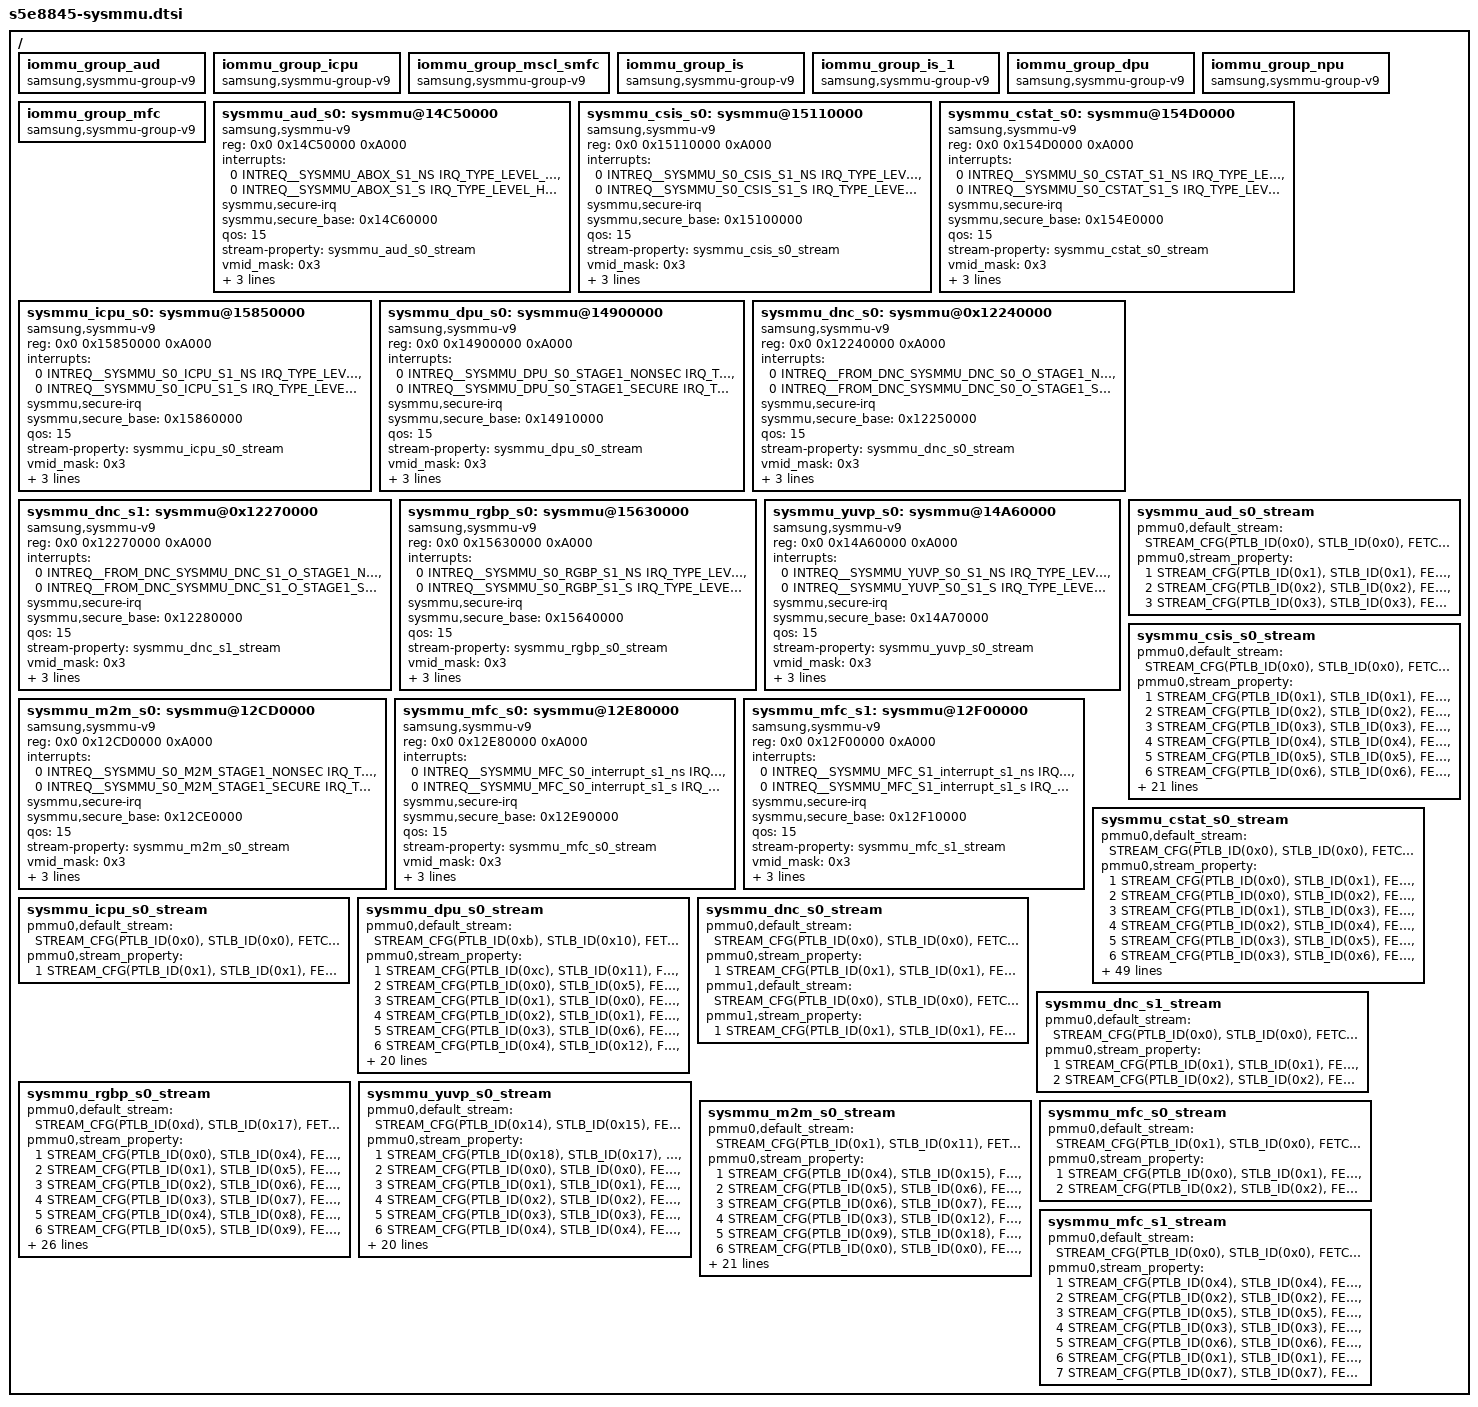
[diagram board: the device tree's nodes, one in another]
// SPDX-License-Identifier: GPL-2.0
/*
 * SAMSUNG S5E8845 SoC device tree source
 *
 * Copyright (c) 2023 Samsung Electronics Co., Ltd.
 *      http://www.samsung.com
 *
 * SAMSUNG S5E8845 SoC device nodes are listed in this file.
 * S5E8845 based board files can include this file and provide
 * values for board specific bindings.
 *
 * This program is free software; you can redistribute it and/or modify
 * it under the terms of the GNU General Public License version 2 as
 * published by the Free Software Foundation.
 */

#include <dt-bindings/interrupt-controller/arm-gic.h>
#include <dt-bindings/soc/samsung,sysmmu-v9.h>

/ {
	iommu_group_aud: iommu_group_aud {
		compatible = "samsung,sysmmu-group-v9";
	};

	iommu_group_icpu: iommu_group_icpu {
		compatible = "samsung,sysmmu-group-v9";
	};

	iommu_group_mscl_smfc: iommu_group_mscl_smfc {
		compatible = "samsung,sysmmu-group-v9";
	};

	iommu_group_is: iommu_group_is {
		compatible = "samsung,sysmmu-group-v9";
	};

	iommu_group_is_1: iommu_group_is_1 {
		compatible = "samsung,sysmmu-group-v9";
	};

	iommu_group_dpu: iommu_group_dpu {
		compatible = "samsung,sysmmu-group-v9";
	};

	iommu_group_npu: iommu_group_npu {
		compatible = "samsung,sysmmu-group-v9";
	};

	iommu_group_mfc: iommu_group_mfc {
		compatible = "samsung,sysmmu-group-v9";
	};

	sysmmu_aud_s0: sysmmu@14C50000 {
		compatible = "samsung,sysmmu-v9";
		reg = <0x0 0x14C50000 0xA000>;
		interrupts = <0 INTREQ__SYSMMU_ABOX_S1_NS IRQ_TYPE_LEVEL_HIGH>,
				<0 INTREQ__SYSMMU_ABOX_S1_S IRQ_TYPE_LEVEL_HIGH>;
		sysmmu,secure-irq;
		sysmmu,secure_base = <0x14C60000>;
		qos = <15>;
		#iommu-cells = <0>;
		stream-property = <&sysmmu_aud_s0_stream>;
		vmid_mask = <0x3>;
		sysmmu,feature-info = <0x1>;
		power-domains = <&pd_aud>;
		port-name = "AUD S0";
	};

	sysmmu_csis_s0: sysmmu@15110000 {
		compatible = "samsung,sysmmu-v9";
		reg = <0x0 0x15110000 0xA000>;
		interrupts = <0 INTREQ__SYSMMU_S0_CSIS_S1_NS IRQ_TYPE_LEVEL_HIGH>,
				<0 INTREQ__SYSMMU_S0_CSIS_S1_S IRQ_TYPE_LEVEL_HIGH>;
		sysmmu,secure-irq;
		sysmmu,secure_base = <0x15100000>;
		qos = <15>;
		#iommu-cells = <0>;
		stream-property = <&sysmmu_csis_s0_stream>;
		vmid_mask = <0x3>;
		sysmmu,feature-info = <0x1>;
		power-domains = <&pd_csis>;
		port-name = "CSIS S0";
	};

	sysmmu_cstat_s0: sysmmu@154D0000 {
		compatible = "samsung,sysmmu-v9";
		reg = <0x0 0x154D0000 0xA000>;
		interrupts = <0 INTREQ__SYSMMU_S0_CSTAT_S1_NS IRQ_TYPE_LEVEL_HIGH>,
				<0 INTREQ__SYSMMU_S0_CSTAT_S1_S IRQ_TYPE_LEVEL_HIGH>;
		sysmmu,secure-irq;
		sysmmu,secure_base = <0x154E0000>;
		qos = <15>;
		#iommu-cells = <0>;
		stream-property = <&sysmmu_cstat_s0_stream>;
		vmid_mask = <0x3>;
		sysmmu,feature-info = <0x1>;
		power-domains = <&pd_cstat>;
		port-name = "CSTAT S0";
	};

	sysmmu_icpu_s0: sysmmu@15850000 {
		compatible = "samsung,sysmmu-v9";
		reg = <0x0 0x15850000 0xA000>;
		interrupts = <0 INTREQ__SYSMMU_S0_ICPU_S1_NS IRQ_TYPE_LEVEL_HIGH>,
				<0 INTREQ__SYSMMU_S0_ICPU_S1_S IRQ_TYPE_LEVEL_HIGH>;
		sysmmu,secure-irq;
		sysmmu,secure_base = <0x15860000>;
		qos = <15>;
		#iommu-cells = <0>;
		stream-property = <&sysmmu_icpu_s0_stream>;
		vmid_mask = <0x3>;
		sysmmu,feature-info = <0x1>;
		power-domains = <&pd_icpu>;
		port-name = "ICPU S0";
	};

	sysmmu_dpu_s0: sysmmu@14900000 {
		compatible = "samsung,sysmmu-v9";
		reg = <0x0 0x14900000 0xA000>;
		interrupts = <0 INTREQ__SYSMMU_DPU_S0_STAGE1_NONSEC IRQ_TYPE_LEVEL_HIGH>,
				<0 INTREQ__SYSMMU_DPU_S0_STAGE1_SECURE IRQ_TYPE_LEVEL_HIGH>;
		sysmmu,secure-irq;
		sysmmu,secure_base = <0x14910000>;
		qos = <15>;
		#iommu-cells = <0>;
		stream-property = <&sysmmu_dpu_s0_stream>;
		vmid_mask = <0x3>;
		sysmmu,feature-info = <0x1>;
		port-name = "DPU_DMA_TOP";
		power-domains = <&pd_dpu>;
	};

	sysmmu_dnc_s0: sysmmu@0x12240000 {
		compatible = "samsung,sysmmu-v9";
		reg = <0x0 0x12240000 0xA000>;
		interrupts = <0 INTREQ__FROM_DNC_SYSMMU_DNC_S0_O_STAGE1_NONSEC IRQ_TYPE_LEVEL_HIGH>,
				<0 INTREQ__FROM_DNC_SYSMMU_DNC_S0_O_STAGE1_SECURE IRQ_TYPE_LEVEL_HIGH>;
		sysmmu,secure-irq;
		sysmmu,secure_base = <0x12250000>;
		qos = <15>;
		#iommu-cells = <0>;
		stream-property = <&sysmmu_dnc_s0_stream>;
		vmid_mask = <0x3>;
		sysmmu,feature-info = <0x1>;
		power-domains = <&pd_dnc>;
		port-name = "DNC S0";
	};

	sysmmu_dnc_s1: sysmmu@0x12270000 {
		compatible = "samsung,sysmmu-v9";
		reg = <0x0 0x12270000 0xA000>;
		interrupts = <0 INTREQ__FROM_DNC_SYSMMU_DNC_S1_O_STAGE1_NONSEC IRQ_TYPE_LEVEL_HIGH>,
				<0 INTREQ__FROM_DNC_SYSMMU_DNC_S1_O_STAGE1_SECURE IRQ_TYPE_LEVEL_HIGH>;
		sysmmu,secure-irq;
		sysmmu,secure_base = <0x12280000>;
		qos = <15>;
		#iommu-cells = <0>;
		stream-property = <&sysmmu_dnc_s1_stream>;
		vmid_mask = <0x3>;
		sysmmu,feature-info = <0x1>;
		power-domains = <&pd_dnc>;
		port-name = "DNC S1";
	};

	sysmmu_rgbp_s0: sysmmu@15630000 {
		compatible = "samsung,sysmmu-v9";
		reg = <0x0 0x15630000 0xA000>;
		interrupts = <0 INTREQ__SYSMMU_S0_RGBP_S1_NS IRQ_TYPE_LEVEL_HIGH>,
				<0 INTREQ__SYSMMU_S0_RGBP_S1_S IRQ_TYPE_LEVEL_HIGH>;
		sysmmu,secure-irq;
		sysmmu,secure_base = <0x15640000>;
		qos = <15>;
		#iommu-cells = <0>;
		stream-property = <&sysmmu_rgbp_s0_stream>;
		vmid_mask = <0x3>;
		sysmmu,feature-info = <0x1>;
		power-domains = <&pd_rgbp>;
		port-name = "RGBP S0";
	};

	sysmmu_yuvp_s0: sysmmu@14A60000 {
		compatible = "samsung,sysmmu-v9";
		reg = <0x0 0x14A60000 0xA000>;
		interrupts = <0 INTREQ__SYSMMU_YUVP_S0_S1_NS IRQ_TYPE_LEVEL_HIGH>,
				<0 INTREQ__SYSMMU_YUVP_S0_S1_S IRQ_TYPE_LEVEL_HIGH>;
		sysmmu,secure-irq;
		sysmmu,secure_base = <0x14A70000>;
		qos = <15>;
		#iommu-cells = <0>;
		stream-property = <&sysmmu_yuvp_s0_stream>;
		vmid_mask = <0x3>;
		sysmmu,feature-info = <0x1>;
		power-domains = <&pd_yuvp>;
		port-name = "YUVP S0";
	};

	sysmmu_m2m_s0: sysmmu@12CD0000 {
		compatible = "samsung,sysmmu-v9";
		reg = <0x0 0x12CD0000 0xA000>;
		interrupts = <0 INTREQ__SYSMMU_S0_M2M_STAGE1_NONSEC IRQ_TYPE_LEVEL_HIGH>,
				<0 INTREQ__SYSMMU_S0_M2M_STAGE1_SECURE IRQ_TYPE_LEVEL_HIGH>;
		sysmmu,secure-irq;
		sysmmu,secure_base = <0x12CE0000>;
		qos = <15>;
		#iommu-cells = <0>;
		stream-property = <&sysmmu_m2m_s0_stream>;
		vmid_mask = <0x3>;
		sysmmu,feature-info = <0x1>;
		power-domains = <&pd_m2m>;
		port-name = "M2M S0";
	};

	sysmmu_mfc_s0: sysmmu@12E80000 {
		compatible = "samsung,sysmmu-v9";
		reg = <0x0 0x12E80000 0xA000>;
		interrupts = <0 INTREQ__SYSMMU_MFC_S0_interrupt_s1_ns IRQ_TYPE_LEVEL_HIGH>,
				<0 INTREQ__SYSMMU_MFC_S0_interrupt_s1_s IRQ_TYPE_LEVEL_HIGH>;
		sysmmu,secure-irq;
		sysmmu,secure_base = <0x12E90000>;
		qos = <15>;
		#iommu-cells = <0>;
		stream-property = <&sysmmu_mfc_s0_stream>;
		vmid_mask = <0x3>;
		sysmmu,feature-info = <0x1>;
		power-domains = <&pd_mfc>;
		port-name = "MFC S0";
	};

	sysmmu_mfc_s1: sysmmu@12F00000 {
		compatible = "samsung,sysmmu-v9";
		reg = <0x0 0x12F00000 0xA000>;
		interrupts = <0 INTREQ__SYSMMU_MFC_S1_interrupt_s1_ns IRQ_TYPE_LEVEL_HIGH>,
				<0 INTREQ__SYSMMU_MFC_S1_interrupt_s1_s IRQ_TYPE_LEVEL_HIGH>;
		sysmmu,secure-irq;
		sysmmu,secure_base = <0x12F10000>;
		qos = <15>;
		#iommu-cells = <0>;
		stream-property = <&sysmmu_mfc_s1_stream>;
		vmid_mask = <0x3>;
		sysmmu,feature-info = <0x1>;
		power-domains = <&pd_mfc>;
		port-name = "MFC S1";
	};

	sysmmu_aud_s0_stream: sysmmu_aud_s0_stream {
		pmmu0,default_stream =
		<STREAM_CFG(PTLB_ID(0x0), STLB_ID(0x0), FETCH_SIZE(SIZE1), PTLB_DIS, STLB_DIS)>;
		pmmu0,stream_property =
		<1 STREAM_CFG(PTLB_ID(0x1), STLB_ID(0x1), FETCH_SIZE(SIZE1), PTLB_DIS, STLB_DIS)
		 STREAM_MATCH_CFG(DIR_RW)
		 STREAM_MATCH_SID_VALUE(0x5)
		 STREAM_MATCH_SID_MASK(0xF)>,
		<2 STREAM_CFG(PTLB_ID(0x2), STLB_ID(0x2), FETCH_SIZE(SIZE1), PTLB_DIS, STLB_DIS)
		 STREAM_MATCH_CFG(DIR_WRITE)
		 STREAM_MATCH_SID_VALUE(0x6)
		 STREAM_MATCH_SID_MASK(0xF)>,
		<3 STREAM_CFG(PTLB_ID(0x3), STLB_ID(0x3), FETCH_SIZE(SIZE1), PTLB_DIS, STLB_DIS)
		 STREAM_MATCH_CFG(DIR_WRITE)
		 STREAM_MATCH_SID_VALUE(0x7)
		 STREAM_MATCH_SID_MASK(0xF)>;
	};

	sysmmu_csis_s0_stream: sysmmu_csis_s0_stream {
		pmmu0,default_stream =
		<STREAM_CFG(PTLB_ID(0x0), STLB_ID(0x0), FETCH_SIZE(SIZE1), PTLB_EN, STLB_EN)>;
		pmmu0,stream_property =
		<1 STREAM_CFG(PTLB_ID(0x1), STLB_ID(0x1), FETCH_SIZE(SIZE1), PTLB_EN, STLB_EN)
		 STREAM_MATCH_CFG(DIR_WRITE)
		 STREAM_MATCH_SID_VALUE(0x2)
		 STREAM_MATCH_SID_MASK(0xF)>,
		<2 STREAM_CFG(PTLB_ID(0x2), STLB_ID(0x2), FETCH_SIZE(SIZE1), PTLB_EN, STLB_EN)
		 STREAM_MATCH_CFG(DIR_WRITE)
		 STREAM_MATCH_SID_VALUE(0x4)
		 STREAM_MATCH_SID_MASK(0xF)>,
		<3 STREAM_CFG(PTLB_ID(0x3), STLB_ID(0x3), FETCH_SIZE(SIZE1), PTLB_EN, STLB_EN)
		 STREAM_MATCH_CFG(DIR_WRITE)
		 STREAM_MATCH_SID_VALUE(0x8)
		 STREAM_MATCH_SID_MASK(0xF)>,
		<4 STREAM_CFG(PTLB_ID(0x4), STLB_ID(0x4), FETCH_SIZE(SIZE1), PTLB_EN, STLB_EN)
		 STREAM_MATCH_CFG(DIR_WRITE)
		 STREAM_MATCH_SID_VALUE(0xC)
		 STREAM_MATCH_SID_MASK(0xF)>,
		<5 STREAM_CFG(PTLB_ID(0x5), STLB_ID(0x5), FETCH_SIZE(SIZE1), PTLB_EN, STLB_EN)
		 STREAM_MATCH_CFG(DIR_WRITE)
		 STREAM_MATCH_SID_VALUE(0x1)
		 STREAM_MATCH_SID_MASK(0xF)>,
		<6 STREAM_CFG(PTLB_ID(0x6), STLB_ID(0x6), FETCH_SIZE(SIZE1), PTLB_EN, STLB_EN)
		 STREAM_MATCH_CFG(DIR_WRITE)
		 STREAM_MATCH_SID_VALUE(0x3)
		 STREAM_MATCH_SID_MASK(0xF)>,
		<7 STREAM_CFG(PTLB_ID(0x7), STLB_ID(0x7), FETCH_SIZE(SIZE1), PTLB_EN, STLB_EN)
		 STREAM_MATCH_CFG(DIR_WRITE)
		 STREAM_MATCH_SID_VALUE(0x5)
		 STREAM_MATCH_SID_MASK(0xF)>,
		<8 STREAM_CFG(PTLB_ID(0x8), STLB_ID(0x8), FETCH_SIZE(SIZE1), PTLB_EN, STLB_EN)
		 STREAM_MATCH_CFG(DIR_WRITE)
		 STREAM_MATCH_SID_VALUE(0x9)
		 STREAM_MATCH_SID_MASK(0xF)>,
		<9 STREAM_CFG(PTLB_ID(0x9), STLB_ID(0x9), FETCH_SIZE(SIZE1), PTLB_EN, STLB_EN)
		 STREAM_MATCH_CFG(DIR_WRITE)
		 STREAM_MATCH_SID_VALUE(0xD)
		 STREAM_MATCH_SID_MASK(0xF)>;
		pmmu1,default_stream =
		<STREAM_CFG(PTLB_ID(0x0), STLB_ID(0xA), FETCH_SIZE(SIZE1), PTLB_EN, STLB_EN)>;
		pmmu1,stream_property =
		<1 STREAM_CFG(PTLB_ID(0x1), STLB_ID(0xB), FETCH_SIZE(SIZE1), PTLB_EN, STLB_EN)
		 STREAM_MATCH_CFG(DIR_WRITE)
		 STREAM_MATCH_SID_VALUE(0x8)
		 STREAM_MATCH_SID_MASK(0xFF)>,
		<2 STREAM_CFG(PTLB_ID(0x2), STLB_ID(0xC), FETCH_SIZE(SIZE1), PTLB_EN, STLB_EN)
		 STREAM_MATCH_CFG(DIR_WRITE)
		 STREAM_MATCH_SID_VALUE(0x10)
		 STREAM_MATCH_SID_MASK(0xFF)>,
		<3 STREAM_CFG(PTLB_ID(0x3), STLB_ID(0xD), FETCH_SIZE(SIZE1), PTLB_EN, STLB_EN)
		 STREAM_MATCH_CFG(DIR_WRITE)
		 STREAM_MATCH_SID_VALUE(0x20)
		 STREAM_MATCH_SID_MASK(0xFF)>,
		<4 STREAM_CFG(PTLB_ID(0x4), STLB_ID(0xE), FETCH_SIZE(SIZE1), PTLB_EN, STLB_EN)
		 STREAM_MATCH_CFG(DIR_WRITE)
		 STREAM_MATCH_SID_VALUE(0x30)
		 STREAM_MATCH_SID_MASK(0xFF)>,
		<5 STREAM_CFG(PTLB_ID(0x5), STLB_ID(0xF), FETCH_SIZE(SIZE1), PTLB_EN, STLB_EN)
		 STREAM_MATCH_CFG(DIR_WRITE)
		 STREAM_MATCH_SID_VALUE(0x1)
		 STREAM_MATCH_SID_MASK(0xFF)>,
		<6 STREAM_CFG(PTLB_ID(0x6), STLB_ID(0x10), FETCH_SIZE(SIZE1), PTLB_EN, STLB_EN)
		 STREAM_MATCH_CFG(DIR_WRITE)
		 STREAM_MATCH_SID_VALUE(0x9)
		 STREAM_MATCH_SID_MASK(0xFF)>,
		<7 STREAM_CFG(PTLB_ID(0x7), STLB_ID(0x11), FETCH_SIZE(SIZE1), PTLB_EN, STLB_EN)
		 STREAM_MATCH_CFG(DIR_WRITE)
		 STREAM_MATCH_SID_VALUE(0x11)
		 STREAM_MATCH_SID_MASK(0xFF)>,
		<8 STREAM_CFG(PTLB_ID(0x8), STLB_ID(0x12), FETCH_SIZE(SIZE1), PTLB_EN, STLB_EN)
		 STREAM_MATCH_CFG(DIR_WRITE)
		 STREAM_MATCH_SID_VALUE(0x21)
		 STREAM_MATCH_SID_MASK(0xFF)>,
		<9 STREAM_CFG(PTLB_ID(0x9), STLB_ID(0x13), FETCH_SIZE(SIZE1), PTLB_EN, STLB_EN)
		 STREAM_MATCH_CFG(DIR_WRITE)
		 STREAM_MATCH_SID_VALUE(0x31)
		 STREAM_MATCH_SID_MASK(0xFF)>,
		<10 STREAM_CFG(PTLB_ID(0xA), STLB_ID(0x14), FETCH_SIZE(SIZE1), PTLB_EN, STLB_EN)
		 STREAM_MATCH_CFG(DIR_READ)
		 STREAM_MATCH_SID_VALUE(0x2)
		 STREAM_MATCH_SID_MASK(0xFF)>,
		<11 STREAM_CFG(PTLB_ID(0xB), STLB_ID(0x15), FETCH_SIZE(SIZE1), PTLB_EN, STLB_EN)
		 STREAM_MATCH_CFG(DIR_WRITE)
		 STREAM_MATCH_SID_VALUE(0x2)
		 STREAM_MATCH_SID_MASK(0xFF)>,
		<12 STREAM_CFG(PTLB_ID(0xC), STLB_ID(0x16), FETCH_SIZE(SIZE1), PTLB_EN, STLB_EN)
		 STREAM_MATCH_CFG(DIR_WRITE)
		 STREAM_MATCH_SID_VALUE(0x42)
		 STREAM_MATCH_SID_MASK(0xFF)>,
		<13 STREAM_CFG(PTLB_ID(0xD), STLB_ID(0x17), FETCH_SIZE(SIZE1), PTLB_EN, STLB_EN)
		 STREAM_MATCH_CFG(DIR_WRITE)
		 STREAM_MATCH_SID_VALUE(0x82)
		 STREAM_MATCH_SID_MASK(0xFF)>,
		<14 STREAM_CFG(PTLB_ID(0xF), STLB_ID(0x19), FETCH_SIZE(SIZE1), PTLB_EN, STLB_DIS)
		 STREAM_MATCH_CFG(DIR_WRITE)
		 STREAM_MATCH_SID_VALUE(0x3)
		 STREAM_MATCH_SID_MASK(0x1)>,
		<15 STREAM_CFG(PTLB_ID(0xE), STLB_ID(0x18), FETCH_SIZE(SIZE1), PTLB_EN, STLB_DIS)
		 STREAM_MATCH_CFG(DIR_WRITE)
		 STREAM_MATCH_SID_VALUE(0x4)
		 STREAM_MATCH_SID_MASK(0x1)>;
	};

	sysmmu_cstat_s0_stream: sysmmu_cstat_s0_stream {
		pmmu0,default_stream =
		<STREAM_CFG(PTLB_ID(0x0), STLB_ID(0x0), FETCH_SIZE(SIZE1), PTLB_DIS, STLB_EN)>;
		pmmu0,stream_property =
		<1 STREAM_CFG(PTLB_ID(0x0), STLB_ID(0x1), FETCH_SIZE(SIZE1), PTLB_DIS, STLB_EN)
		 STREAM_MATCH_CFG(DIR_WRITE)
		 STREAM_MATCH_SID_VALUE(0x80)
		 STREAM_MATCH_SID_MASK(0x1FF)>,
		<2 STREAM_CFG(PTLB_ID(0x0), STLB_ID(0x2), FETCH_SIZE(SIZE1), PTLB_DIS, STLB_EN)
		 STREAM_MATCH_CFG(DIR_WRITE)
		 STREAM_MATCH_SID_VALUE(0x100)
		 STREAM_MATCH_SID_MASK(0x1FF)>,
		<3 STREAM_CFG(PTLB_ID(0x1), STLB_ID(0x3), FETCH_SIZE(SIZE1), PTLB_EN, STLB_EN)
		 STREAM_MATCH_CFG(DIR_READ)
		 STREAM_MATCH_SID_VALUE(0x0)
		 STREAM_MATCH_SID_MASK(0x1)>,
		<4 STREAM_CFG(PTLB_ID(0x2), STLB_ID(0x4), FETCH_SIZE(SIZE1), PTLB_EN, STLB_EN)
		 STREAM_MATCH_CFG(DIR_READ)
		 STREAM_MATCH_SID_VALUE(0x10)
		 STREAM_MATCH_SID_MASK(0x1)>,
		<5 STREAM_CFG(PTLB_ID(0x3), STLB_ID(0x5), FETCH_SIZE(SIZE1), PTLB_DIS, STLB_EN)
		 STREAM_MATCH_CFG(DIR_WRITE)
		 STREAM_MATCH_SID_VALUE(0x1)
		 STREAM_MATCH_SID_MASK(0x1F)>,
		<6 STREAM_CFG(PTLB_ID(0x3), STLB_ID(0x6), FETCH_SIZE(SIZE1), PTLB_DIS, STLB_EN)
		 STREAM_MATCH_CFG(DIR_WRITE)
		 STREAM_MATCH_SID_VALUE(0x21)
		 STREAM_MATCH_SID_MASK(0x1F)>,
		<7 STREAM_CFG(PTLB_ID(0x3), STLB_ID(0x7), FETCH_SIZE(SIZE1), PTLB_DIS, STLB_EN)
		 STREAM_MATCH_CFG(DIR_WRITE)
		 STREAM_MATCH_SID_VALUE(0x41)
		 STREAM_MATCH_SID_MASK(0x1F)>,
		<8 STREAM_CFG(PTLB_ID(0x4), STLB_ID(0x8), FETCH_SIZE(SIZE1), PTLB_EN, STLB_EN)
		 STREAM_MATCH_CFG(DIR_READ)
		 STREAM_MATCH_SID_VALUE(0x1)
		 STREAM_MATCH_SID_MASK(0x1)>,
		<9 STREAM_CFG(PTLB_ID(0x5), STLB_ID(0x9), FETCH_SIZE(SIZE1), PTLB_DIS, STLB_EN)
		 STREAM_MATCH_CFG(DIR_WRITE)
		 STREAM_MATCH_SID_VALUE(0x2)
		 STREAM_MATCH_SID_MASK(0x1F)>,
		<10 STREAM_CFG(PTLB_ID(0x5), STLB_ID(0xA), FETCH_SIZE(SIZE1), PTLB_DIS, STLB_EN)
		 STREAM_MATCH_CFG(DIR_WRITE)
		 STREAM_MATCH_SID_VALUE(0x82)
		 STREAM_MATCH_SID_MASK(0x1F)>,
		<11 STREAM_CFG(PTLB_ID(0x5), STLB_ID(0xB), FETCH_SIZE(SIZE1), PTLB_DIS, STLB_EN)
		 STREAM_MATCH_CFG(DIR_WRITE)
		 STREAM_MATCH_SID_VALUE(0x102)
		 STREAM_MATCH_SID_MASK(0x1F)>,
		<12 STREAM_CFG(PTLB_ID(0x6), STLB_ID(0xC), FETCH_SIZE(SIZE1), PTLB_EN, STLB_EN)
		 STREAM_MATCH_CFG(DIR_READ)
		 STREAM_MATCH_SID_VALUE(0x2)
		 STREAM_MATCH_SID_MASK(0x1)>,
		<13 STREAM_CFG(PTLB_ID(0x7), STLB_ID(0xD), FETCH_SIZE(SIZE1), PTLB_DIS, STLB_EN)
		 STREAM_MATCH_CFG(DIR_WRITE)
		 STREAM_MATCH_SID_VALUE(0x3)
		 STREAM_MATCH_SID_MASK(0x1F)>,
		<14 STREAM_CFG(PTLB_ID(0x7), STLB_ID(0xE), FETCH_SIZE(SIZE1), PTLB_DIS, STLB_EN)
		 STREAM_MATCH_CFG(DIR_WRITE)
		 STREAM_MATCH_SID_VALUE(0x83)
		 STREAM_MATCH_SID_MASK(0x1F)>,
		<15 STREAM_CFG(PTLB_ID(0x7), STLB_ID(0xF), FETCH_SIZE(SIZE1), PTLB_DIS, STLB_EN)
		 STREAM_MATCH_CFG(DIR_WRITE)
		 STREAM_MATCH_SID_VALUE(0x103)
		 STREAM_MATCH_SID_MASK(0x1F)>,
		<16 STREAM_CFG(PTLB_ID(0x8), STLB_ID(0x10), FETCH_SIZE(SIZE1), PTLB_DIS, STLB_EN)
		 STREAM_MATCH_CFG(DIR_WRITE)
		 STREAM_MATCH_SID_VALUE(0x4)
		 STREAM_MATCH_SID_MASK(0x1F)>,
		<17 STREAM_CFG(PTLB_ID(0x8), STLB_ID(0x11), FETCH_SIZE(SIZE1), PTLB_DIS, STLB_EN)
		 STREAM_MATCH_CFG(DIR_WRITE)
		 STREAM_MATCH_SID_VALUE(0x84)
		 STREAM_MATCH_SID_MASK(0x1F)>,
		<18 STREAM_CFG(PTLB_ID(0x8), STLB_ID(0x12), FETCH_SIZE(SIZE1), PTLB_DIS, STLB_EN)
		 STREAM_MATCH_CFG(DIR_WRITE)
		 STREAM_MATCH_SID_VALUE(0x104)
		 STREAM_MATCH_SID_MASK(0x1F)>,
		<19 STREAM_CFG(PTLB_ID(0x10), STLB_ID(0x2F), FETCH_SIZE(SIZE1), PTLB_DIS, STLB_DIS)
		 STREAM_MATCH_CFG(DIR_READ)
		 STREAM_MATCH_SID_VALUE(0x4)
		 STREAM_MATCH_SID_MASK(0x1)>,
		<20 STREAM_CFG(PTLB_ID(0x9), STLB_ID(0x13), FETCH_SIZE(SIZE1), PTLB_DIS, STLB_EN)
		 STREAM_MATCH_CFG(DIR_WRITE)
		 STREAM_MATCH_SID_VALUE(0x5)
		 STREAM_MATCH_SID_MASK(0x1F)>,
		<21 STREAM_CFG(PTLB_ID(0x9), STLB_ID(0x14), FETCH_SIZE(SIZE1), PTLB_DIS, STLB_EN)
		 STREAM_MATCH_CFG(DIR_WRITE)
		 STREAM_MATCH_SID_VALUE(0x85)
		 STREAM_MATCH_SID_MASK(0x1F)>,
		<22 STREAM_CFG(PTLB_ID(0x9), STLB_ID(0x15), FETCH_SIZE(SIZE1), PTLB_DIS, STLB_EN)
		 STREAM_MATCH_CFG(DIR_WRITE)
		 STREAM_MATCH_SID_VALUE(0x105)
		 STREAM_MATCH_SID_MASK(0x1F)>,
		<23 STREAM_CFG(PTLB_ID(0x11), STLB_ID(0x30), FETCH_SIZE(SIZE1), PTLB_DIS, STLB_DIS)
		 STREAM_MATCH_CFG(DIR_READ)
		 STREAM_MATCH_SID_VALUE(0x5)
		 STREAM_MATCH_SID_MASK(0x1)>,
		<24 STREAM_CFG(PTLB_ID(0xA), STLB_ID(0x16), FETCH_SIZE(SIZE1), PTLB_DIS, STLB_EN)
		 STREAM_MATCH_CFG(DIR_WRITE)
		 STREAM_MATCH_SID_VALUE(0x6)
		 STREAM_MATCH_SID_MASK(0x1F)>,
		<25 STREAM_CFG(PTLB_ID(0xA), STLB_ID(0x17), FETCH_SIZE(SIZE1), PTLB_DIS, STLB_EN)
		 STREAM_MATCH_CFG(DIR_WRITE)
		 STREAM_MATCH_SID_VALUE(0x86)
		 STREAM_MATCH_SID_MASK(0x1F)>,
		<26 STREAM_CFG(PTLB_ID(0xA), STLB_ID(0x18), FETCH_SIZE(SIZE1), PTLB_DIS, STLB_EN)
		 STREAM_MATCH_CFG(DIR_WRITE)
		 STREAM_MATCH_SID_VALUE(0x106)
		 STREAM_MATCH_SID_MASK(0x1F)>,
		<27 STREAM_CFG(PTLB_ID(0x12), STLB_ID(0x31), FETCH_SIZE(SIZE1), PTLB_DIS, STLB_DIS)
		 STREAM_MATCH_CFG(DIR_READ)
		 STREAM_MATCH_SID_VALUE(0x6)
		 STREAM_MATCH_SID_MASK(0x1)>,
		<28 STREAM_CFG(PTLB_ID(0xB), STLB_ID(0x19), FETCH_SIZE(SIZE1), PTLB_DIS, STLB_EN)
		 STREAM_MATCH_CFG(DIR_WRITE)
		 STREAM_MATCH_SID_VALUE(0x7)
		 STREAM_MATCH_SID_MASK(0x1F)>,
		<29 STREAM_CFG(PTLB_ID(0xB), STLB_ID(0x1A), FETCH_SIZE(SIZE1), PTLB_DIS, STLB_EN)
		 STREAM_MATCH_CFG(DIR_WRITE)
		 STREAM_MATCH_SID_VALUE(0x87)
		 STREAM_MATCH_SID_MASK(0x1F)>,
		<30 STREAM_CFG(PTLB_ID(0xB), STLB_ID(0x1B), FETCH_SIZE(SIZE1), PTLB_DIS, STLB_EN)
		 STREAM_MATCH_CFG(DIR_WRITE)
		 STREAM_MATCH_SID_VALUE(0x107)
		 STREAM_MATCH_SID_MASK(0x1F)>,
		<31 STREAM_CFG(PTLB_ID(0xC), STLB_ID(0x1C), FETCH_SIZE(SIZE1), PTLB_DIS, STLB_EN)
		 STREAM_MATCH_CFG(DIR_WRITE)
		 STREAM_MATCH_SID_VALUE(0x9)
		 STREAM_MATCH_SID_MASK(0x1F)>,
		<32 STREAM_CFG(PTLB_ID(0xC), STLB_ID(0x1D), FETCH_SIZE(SIZE1), PTLB_DIS, STLB_EN)
		 STREAM_MATCH_CFG(DIR_WRITE)
		 STREAM_MATCH_SID_VALUE(0x89)
		 STREAM_MATCH_SID_MASK(0x1F)>,
		<33 STREAM_CFG(PTLB_ID(0xC), STLB_ID(0x1E), FETCH_SIZE(SIZE1), PTLB_DIS, STLB_EN)
		 STREAM_MATCH_CFG(DIR_WRITE)
		 STREAM_MATCH_SID_VALUE(0x109)
		 STREAM_MATCH_SID_MASK(0x1F)>,
		<34 STREAM_CFG(PTLB_ID(0xD), STLB_ID(0x1F), FETCH_SIZE(SIZE1), PTLB_DIS, STLB_EN)
		 STREAM_MATCH_CFG(DIR_WRITE)
		 STREAM_MATCH_SID_VALUE(0x9)
		 STREAM_MATCH_SID_MASK(0x1F)>,
		<35 STREAM_CFG(PTLB_ID(0xD), STLB_ID(0x20), FETCH_SIZE(SIZE1), PTLB_DIS, STLB_EN)
		 STREAM_MATCH_CFG(DIR_WRITE)
		 STREAM_MATCH_SID_VALUE(0x89)
		 STREAM_MATCH_SID_MASK(0x1F)>,
		<36 STREAM_CFG(PTLB_ID(0xD), STLB_ID(0x21), FETCH_SIZE(SIZE1), PTLB_DIS, STLB_EN)
		 STREAM_MATCH_CFG(DIR_WRITE)
		 STREAM_MATCH_SID_VALUE(0x109)
		 STREAM_MATCH_SID_MASK(0x1F)>,
		<37 STREAM_CFG(PTLB_ID(0xE), STLB_ID(0x22), FETCH_SIZE(SIZE1), PTLB_DIS, STLB_EN)
		 STREAM_MATCH_CFG(DIR_WRITE)
		 STREAM_MATCH_SID_VALUE(0x189)
		 STREAM_MATCH_SID_MASK(0x1F)>,
		<38 STREAM_CFG(PTLB_ID(0xE), STLB_ID(0x23), FETCH_SIZE(SIZE1), PTLB_DIS, STLB_EN)
		 STREAM_MATCH_CFG(DIR_WRITE)
		 STREAM_MATCH_SID_VALUE(0x29)
		 STREAM_MATCH_SID_MASK(0x1F)>,
		<39 STREAM_CFG(PTLB_ID(0xE), STLB_ID(0x24), FETCH_SIZE(SIZE1), PTLB_DIS, STLB_EN)
		 STREAM_MATCH_CFG(DIR_WRITE)
		 STREAM_MATCH_SID_VALUE(0xA9)
		 STREAM_MATCH_SID_MASK(0x1F)>,
		<40 STREAM_CFG(PTLB_ID(0xF), STLB_ID(0x25), FETCH_SIZE(SIZE1), PTLB_DIS, STLB_EN)
		 STREAM_MATCH_CFG(DIR_WRITE)
		 STREAM_MATCH_SID_VALUE(0x129)
		 STREAM_MATCH_SID_MASK(0x1F)>,
		<41 STREAM_CFG(PTLB_ID(0xF), STLB_ID(0x26), FETCH_SIZE(SIZE1), PTLB_DIS, STLB_EN)
		 STREAM_MATCH_CFG(DIR_WRITE)
		 STREAM_MATCH_SID_VALUE(0x1A9)
		 STREAM_MATCH_SID_MASK(0x1F)>,
		<42 STREAM_CFG(PTLB_ID(0xF), STLB_ID(0x27), FETCH_SIZE(SIZE1), PTLB_DIS, STLB_EN)
		 STREAM_MATCH_CFG(DIR_WRITE)
		 STREAM_MATCH_SID_VALUE(0x9)
		 STREAM_MATCH_SID_MASK(0x1F)>,
		<43 STREAM_CFG(PTLB_ID(0x13), STLB_ID(0x33), FETCH_SIZE(SIZE1), PTLB_DIS, STLB_DIS)
		 STREAM_MATCH_CFG(DIR_WRITE)
		 STREAM_MATCH_SID_VALUE(0xA)
		 STREAM_MATCH_SID_MASK(0x1)>,
		<44 STREAM_CFG(PTLB_ID(0x14), STLB_ID(0x34), FETCH_SIZE(SIZE1), PTLB_DIS, STLB_DIS)
		 STREAM_MATCH_CFG(DIR_WRITE)
		 STREAM_MATCH_SID_VALUE(0xB)
		 STREAM_MATCH_SID_MASK(0x1)>;
		pmmu1,default_stream =
		<STREAM_CFG(PTLB_ID(0x0), STLB_ID(0x28), FETCH_SIZE(SIZE1), PTLB_EN, STLB_EN)>;
		pmmu1,stream_property =
		<1 STREAM_CFG(PTLB_ID(0x7), STLB_ID(0x32), FETCH_SIZE(SIZE1), PTLB_DIS, STLB_DIS)
		 STREAM_MATCH_CFG(DIR_READ)
		 STREAM_MATCH_SID_VALUE(0x0)
		 STREAM_MATCH_SID_MASK(0xF)>,
		<2 STREAM_CFG(PTLB_ID(0x1), STLB_ID(0x29), FETCH_SIZE(SIZE1), PTLB_EN, STLB_EN)
		 STREAM_MATCH_CFG(DIR_READ)
		 STREAM_MATCH_SID_VALUE(0x1)
		 STREAM_MATCH_SID_MASK(0xF)>,
		<3 STREAM_CFG(PTLB_ID(0x2), STLB_ID(0x2A), FETCH_SIZE(SIZE1), PTLB_EN, STLB_EN)
		 STREAM_MATCH_CFG(DIR_READ)
		 STREAM_MATCH_SID_VALUE(0x9)
		 STREAM_MATCH_SID_MASK(0xF)>,
		<4 STREAM_CFG(PTLB_ID(0x3), STLB_ID(0x2B), FETCH_SIZE(SIZE1), PTLB_EN, STLB_EN)
		 STREAM_MATCH_CFG(DIR_WRITE)
		 STREAM_MATCH_SID_VALUE(0x1)
		 STREAM_MATCH_SID_MASK(0xF)>,
		<5 STREAM_CFG(PTLB_ID(0x4), STLB_ID(0x2C), FETCH_SIZE(SIZE1), PTLB_EN, STLB_EN)
		 STREAM_MATCH_CFG(DIR_WRITE)
		 STREAM_MATCH_SID_VALUE(0x2)
		 STREAM_MATCH_SID_MASK(0xF)>,
		<6 STREAM_CFG(PTLB_ID(0x5), STLB_ID(0x2D), FETCH_SIZE(SIZE1), PTLB_EN, STLB_EN)
		 STREAM_MATCH_CFG(DIR_READ)
		 STREAM_MATCH_SID_VALUE(0x3)
		 STREAM_MATCH_SID_MASK(0xF)>,
		<7 STREAM_CFG(PTLB_ID(0x6), STLB_ID(0x2E), FETCH_SIZE(SIZE1), PTLB_EN, STLB_EN)
		 STREAM_MATCH_CFG(DIR_READ)
		 STREAM_MATCH_SID_VALUE(0xB)
		 STREAM_MATCH_SID_MASK(0xF)>,
		<8 STREAM_CFG(PTLB_ID(0x8), STLB_ID(0x35), FETCH_SIZE(SIZE1), PTLB_DIS, STLB_DIS)
		 STREAM_MATCH_CFG(DIR_WRITE)
		 STREAM_MATCH_SID_VALUE(0x4)
		 STREAM_MATCH_SID_MASK(0xF)>;
	};

	sysmmu_icpu_s0_stream: sysmmu_icpu_s0_stream {
		pmmu0,default_stream =
		<STREAM_CFG(PTLB_ID(0x0), STLB_ID(0x0), FETCH_SIZE(SIZE1), PTLB_DIS, STLB_DIS)>;
		pmmu0,stream_property =
		<1 STREAM_CFG(PTLB_ID(0x1), STLB_ID(0x1), FETCH_SIZE(SIZE1), PTLB_DIS, STLB_DIS)
		 STREAM_MATCH_CFG(DIR_RW)
		 STREAM_MATCH_SID_VALUE(0x1)
		 STREAM_MATCH_SID_MASK(0x1)>;
	};

	sysmmu_dpu_s0_stream: sysmmu_dpu_s0_stream {
		pmmu0,default_stream =
		<STREAM_CFG(PTLB_ID(0xb), STLB_ID(0x10), FETCH_SIZE(SIZE1), PTLB_EN, STLB_EN)>;
		pmmu0,stream_property =
		<1 STREAM_CFG(PTLB_ID(0xc), STLB_ID(0x11), FETCH_SIZE(SIZE1), PTLB_EN, STLB_EN)
		 STREAM_MATCH_CFG(DIR_READ)
		 STREAM_MATCH_SID_VALUE(0x1A)
		 STREAM_MATCH_SID_MASK(0x1F)>,
		<2 STREAM_CFG(PTLB_ID(0x0), STLB_ID(0x5), FETCH_SIZE(SIZE2), PTLB_EN, STLB_EN)
		 STREAM_MATCH_CFG(DIR_READ)
		 STREAM_MATCH_SID_VALUE(0x0)
		 STREAM_MATCH_SID_MASK(0x1F)>,
		<3 STREAM_CFG(PTLB_ID(0x1), STLB_ID(0x0), FETCH_SIZE(SIZE32), PTLB_DIS, STLB_EN)
		 STREAM_MATCH_CFG(DIR_READ)
		 STREAM_MATCH_SID_VALUE(0x4)
		 STREAM_MATCH_SID_MASK(0x1F)>,
		<4 STREAM_CFG(PTLB_ID(0x2), STLB_ID(0x1), FETCH_SIZE(SIZE32), PTLB_DIS, STLB_EN)
		 STREAM_MATCH_CFG(DIR_READ)
		 STREAM_MATCH_SID_VALUE(0x5)
		 STREAM_MATCH_SID_MASK(0x1F)>,
		<5 STREAM_CFG(PTLB_ID(0x3), STLB_ID(0x6), FETCH_SIZE(SIZE2), PTLB_EN, STLB_EN)
		 STREAM_MATCH_CFG(DIR_READ)
		 STREAM_MATCH_SID_VALUE(0x6)
		 STREAM_MATCH_SID_MASK(0x1F)>,
		<6 STREAM_CFG(PTLB_ID(0x4), STLB_ID(0x12), FETCH_SIZE(SIZE1), PTLB_EN, STLB_EN)
		 STREAM_MATCH_CFG(DIR_READ)
		 STREAM_MATCH_SID_VALUE(0x7)
		 STREAM_MATCH_SID_MASK(0x1F)>,
		<7 STREAM_CFG(PTLB_ID(0x5), STLB_ID(0x2), FETCH_SIZE(SIZE16), PTLB_EN, STLB_EN)
		 STREAM_MATCH_CFG(DIR_READ)
		 STREAM_MATCH_SID_VALUE(0x8)
		 STREAM_MATCH_SID_MASK(0x1F)>,
		<8 STREAM_CFG(PTLB_ID(0x6), STLB_ID(0x7), FETCH_SIZE(SIZE2), PTLB_EN, STLB_EN)
		 STREAM_MATCH_CFG(DIR_READ)
		 STREAM_MATCH_SID_VALUE(0xA)
		 STREAM_MATCH_SID_MASK(0x1F)>,
		<9 STREAM_CFG(PTLB_ID(0x7), STLB_ID(0x8), FETCH_SIZE(SIZE2), PTLB_EN, STLB_EN)
		 STREAM_MATCH_CFG(DIR_READ)
		 STREAM_MATCH_SID_VALUE(0xC)
		 STREAM_MATCH_SID_MASK(0x1F)>,
		<10 STREAM_CFG(PTLB_ID(0x8), STLB_ID(0x9), FETCH_SIZE(SIZE2), PTLB_EN, STLB_EN)
		 STREAM_MATCH_CFG(DIR_READ)
		 STREAM_MATCH_SID_VALUE(0xD)
		 STREAM_MATCH_SID_MASK(0x1F)>,
		<11 STREAM_CFG(PTLB_ID(0x9), STLB_ID(0x13), FETCH_SIZE(SIZE1), PTLB_EN, STLB_EN)
		 STREAM_MATCH_CFG(DIR_READ)
		 STREAM_MATCH_SID_VALUE(0xE)
		 STREAM_MATCH_SID_MASK(0x1F)>,
		<12 STREAM_CFG(PTLB_ID(0xa), STLB_ID(0x14), FETCH_SIZE(SIZE1), PTLB_EN, STLB_EN)
		 STREAM_MATCH_CFG(DIR_READ)
		 STREAM_MATCH_SID_VALUE(0xF)
		 STREAM_MATCH_SID_MASK(0x1F)>;
		pmmu1,default_stream =
		<STREAM_CFG(PTLB_ID(0xB), STLB_ID(0x18), FETCH_SIZE(SIZE1), PTLB_EN, STLB_DIS)>;
		pmmu1,stream_property =
		<1 STREAM_CFG(PTLB_ID(0x0), STLB_ID(0x3), FETCH_SIZE(SIZE16), PTLB_EN, STLB_EN)
		 STREAM_MATCH_CFG(DIR_READ)
		 STREAM_MATCH_SID_VALUE(0x0)
		 STREAM_MATCH_SID_MASK(0x1F)>,
		<2 STREAM_CFG(PTLB_ID(0x1), STLB_ID(0xA), FETCH_SIZE(SIZE2), PTLB_EN, STLB_EN)
		 STREAM_MATCH_CFG(DIR_READ)
		 STREAM_MATCH_SID_VALUE(0x2)
		 STREAM_MATCH_SID_MASK(0x1F)>,
		<3 STREAM_CFG(PTLB_ID(0x2), STLB_ID(0xb), FETCH_SIZE(SIZE1), PTLB_EN, STLB_EN)
		 STREAM_MATCH_CFG(DIR_READ)
		 STREAM_MATCH_SID_VALUE(0x4)
		 STREAM_MATCH_SID_MASK(0x1F)>,
		<4 STREAM_CFG(PTLB_ID(0x3), STLB_ID(0xc), FETCH_SIZE(SIZE1), PTLB_EN, STLB_EN)
		 STREAM_MATCH_CFG(DIR_READ)
		 STREAM_MATCH_SID_VALUE(0x5)
		 STREAM_MATCH_SID_MASK(0x1F)>,
		<5 STREAM_CFG(PTLB_ID(0x4), STLB_ID(0xd), FETCH_SIZE(SIZE1), PTLB_EN, STLB_EN)
		 STREAM_MATCH_CFG(DIR_READ)
		 STREAM_MATCH_SID_VALUE(0x8)
		 STREAM_MATCH_SID_MASK(0x1F)>,
		<6 STREAM_CFG(PTLB_ID(0x5), STLB_ID(0x4), FETCH_SIZE(SIZE16), PTLB_EN, STLB_EN)
		 STREAM_MATCH_CFG(DIR_READ)
		 STREAM_MATCH_SID_VALUE(0xC)
		 STREAM_MATCH_SID_MASK(0x1F)>,
		<7 STREAM_CFG(PTLB_ID(0x6), STLB_ID(0xe), FETCH_SIZE(SIZE2), PTLB_EN, STLB_EN)
		 STREAM_MATCH_CFG(DIR_READ)
		 STREAM_MATCH_SID_VALUE(0xD)
		 STREAM_MATCH_SID_MASK(0x1F)>,
		<8 STREAM_CFG(PTLB_ID(0x7), STLB_ID(0xf), FETCH_SIZE(SIZE1), PTLB_EN, STLB_EN)
		 STREAM_MATCH_CFG(DIR_READ)
		 STREAM_MATCH_SID_VALUE(0xE)
		 STREAM_MATCH_SID_MASK(0x1F)>,
		<9 STREAM_CFG(PTLB_ID(0x8), STLB_ID(0x15), FETCH_SIZE(SIZE1), PTLB_EN, STLB_EN)
		 STREAM_MATCH_CFG(DIR_READ)
		 STREAM_MATCH_SID_VALUE(0xF)
		 STREAM_MATCH_SID_MASK(0x1F)>,
		<10 STREAM_CFG(PTLB_ID(0x9), STLB_ID(0x16), FETCH_SIZE(SIZE1), PTLB_EN, STLB_EN)
		 STREAM_MATCH_CFG(DIR_WRITE)
		 STREAM_MATCH_SID_VALUE(0x0)
		 STREAM_MATCH_SID_MASK(0x1F)>,
		<11 STREAM_CFG(PTLB_ID(0xA), STLB_ID(0x17), FETCH_SIZE(SIZE1), PTLB_EN, STLB_EN)
		 STREAM_MATCH_CFG(DIR_WRITE)
		 STREAM_MATCH_SID_VALUE(0x1)
		 STREAM_MATCH_SID_MASK(0xF)>;
	};

	sysmmu_dnc_s0_stream: sysmmu_dnc_s0_stream {
		pmmu0,default_stream =
		<STREAM_CFG(PTLB_ID(0x0), STLB_ID(0x0), FETCH_SIZE(SIZE8), PTLB_EN, STLB_EN)>;
		pmmu0,stream_property =
		<1 STREAM_CFG(PTLB_ID(0x1), STLB_ID(0x1), FETCH_SIZE(SIZE1), PTLB_DIS, STLB_DIS)
		 STREAM_MATCH_CFG(DIR_RW)
		 STREAM_MATCH_SID_VALUE(0x20)
		 STREAM_MATCH_SID_MASK(0x3F)>;
		pmmu1,default_stream =
		<STREAM_CFG(PTLB_ID(0x0), STLB_ID(0x0), FETCH_SIZE(SIZE64), PTLB_DIS, STLB_DIS)>;
		pmmu1,stream_property =
		<1 STREAM_CFG(PTLB_ID(0x1), STLB_ID(0x1), FETCH_SIZE(SIZE64), PTLB_DIS, STLB_DIS)
		 STREAM_MATCH_CFG(DIR_RW)
		 STREAM_MATCH_SID_VALUE(0x20)
		 STREAM_MATCH_SID_MASK(0x3F)>;
	};

	sysmmu_dnc_s1_stream: sysmmu_dnc_s1_stream {
		pmmu0,default_stream =
		<STREAM_CFG(PTLB_ID(0x0), STLB_ID(0x0), FETCH_SIZE(SIZE1), PTLB_DIS, STLB_DIS)>;
		pmmu0,stream_property =
		<1 STREAM_CFG(PTLB_ID(0x1), STLB_ID(0x1), FETCH_SIZE(SIZE1), PTLB_DIS, STLB_EN)
		 STREAM_MATCH_CFG(DIR_READ)
		 STREAM_MATCH_SID_VALUE(0x1)
		 STREAM_MATCH_SID_MASK(0xF)>,
		<2 STREAM_CFG(PTLB_ID(0x2), STLB_ID(0x2), FETCH_SIZE(SIZE1), PTLB_DIS, STLB_DIS)
		 STREAM_MATCH_CFG(DIR_WRITE)
		 STREAM_MATCH_SID_VALUE(0x2)
		 STREAM_MATCH_SID_MASK(0xF)>;
	};

	sysmmu_rgbp_s0_stream: sysmmu_rgbp_s0_stream {
		pmmu0,default_stream =
		<STREAM_CFG(PTLB_ID(0xd), STLB_ID(0x17), FETCH_SIZE(SIZE1), PTLB_DIS, STLB_DIS)>;
		pmmu0,stream_property =
		<1 STREAM_CFG(PTLB_ID(0x0), STLB_ID(0x4), FETCH_SIZE(SIZE1), PTLB_EN, STLB_EN)
		 STREAM_MATCH_CFG(DIR_WRITE)
		 STREAM_MATCH_SID_VALUE(0x0)
		 STREAM_MATCH_SID_MASK(0x1F)>,
		<2 STREAM_CFG(PTLB_ID(0x1), STLB_ID(0x5), FETCH_SIZE(SIZE1), PTLB_EN, STLB_EN)
		 STREAM_MATCH_CFG(DIR_WRITE)
		 STREAM_MATCH_SID_VALUE(0x10)
		 STREAM_MATCH_SID_MASK(0x1F)>,
		<3 STREAM_CFG(PTLB_ID(0x2), STLB_ID(0x6), FETCH_SIZE(SIZE1), PTLB_EN, STLB_EN)
		 STREAM_MATCH_CFG(DIR_WRITE)
		 STREAM_MATCH_SID_VALUE(0x1)
		 STREAM_MATCH_SID_MASK(0x1F)>,
		<4 STREAM_CFG(PTLB_ID(0x3), STLB_ID(0x7), FETCH_SIZE(SIZE1), PTLB_EN, STLB_EN)
		 STREAM_MATCH_CFG(DIR_READ)
		 STREAM_MATCH_SID_VALUE(0x2)
		 STREAM_MATCH_SID_MASK(0x1F)>,
		<5 STREAM_CFG(PTLB_ID(0x4), STLB_ID(0x8), FETCH_SIZE(SIZE1), PTLB_EN, STLB_EN)
		 STREAM_MATCH_CFG(DIR_WRITE)
		 STREAM_MATCH_SID_VALUE(0x2)
		 STREAM_MATCH_SID_MASK(0x1F)>,
		<6 STREAM_CFG(PTLB_ID(0x5), STLB_ID(0x9), FETCH_SIZE(SIZE1), PTLB_EN, STLB_EN)
		 STREAM_MATCH_CFG(DIR_WRITE)
		 STREAM_MATCH_SID_VALUE(0x12)
		 STREAM_MATCH_SID_MASK(0x1F)>,
		<7 STREAM_CFG(PTLB_ID(0xE), STLB_ID(0x19), FETCH_SIZE(SIZE1), PTLB_DIS, STLB_DIS)
		 STREAM_MATCH_CFG(DIR_WRITE)
		 STREAM_MATCH_SID_VALUE(0x3)
		 STREAM_MATCH_SID_MASK(0x1F)>,
		<8 STREAM_CFG(PTLB_ID(0xF), STLB_ID(0x1A), FETCH_SIZE(SIZE1), PTLB_DIS, STLB_DIS)
		 STREAM_MATCH_CFG(DIR_WRITE)
		 STREAM_MATCH_SID_VALUE(0x4)
		 STREAM_MATCH_SID_MASK(0x1F)>,
		<9 STREAM_CFG(PTLB_ID(0x6), STLB_ID(0xA), FETCH_SIZE(SIZE1), PTLB_EN, STLB_EN)
		 STREAM_MATCH_CFG(DIR_READ)
		 STREAM_MATCH_SID_VALUE(0x5)
		 STREAM_MATCH_SID_MASK(0x1F)>,
		<10 STREAM_CFG(PTLB_ID(0x7), STLB_ID(0xB), FETCH_SIZE(SIZE1), PTLB_EN, STLB_EN)
		 STREAM_MATCH_CFG(DIR_READ)
		 STREAM_MATCH_SID_VALUE(0x6)
		 STREAM_MATCH_SID_MASK(0x1F)>,
		<11 STREAM_CFG(PTLB_ID(0x8), STLB_ID(0xC), FETCH_SIZE(SIZE1), PTLB_EN, STLB_EN)
		 STREAM_MATCH_CFG(DIR_READ)
		 STREAM_MATCH_SID_VALUE(0x7)
		 STREAM_MATCH_SID_MASK(0x1F)>,
		<12 STREAM_CFG(PTLB_ID(0x9), STLB_ID(0xD), FETCH_SIZE(SIZE1), PTLB_EN, STLB_EN)
		 STREAM_MATCH_CFG(DIR_READ)
		 STREAM_MATCH_SID_VALUE(0x7)
		 STREAM_MATCH_SID_MASK(0x1F)>,
		<13 STREAM_CFG(PTLB_ID(0xA), STLB_ID(0xE), FETCH_SIZE(SIZE1), PTLB_EN, STLB_EN)
		 STREAM_MATCH_CFG(DIR_READ)
		 STREAM_MATCH_SID_VALUE(0xA)
		 STREAM_MATCH_SID_MASK(0x1F)>,
		<14 STREAM_CFG(PTLB_ID(0xB), STLB_ID(0xF), FETCH_SIZE(SIZE1), PTLB_EN, STLB_EN)
		 STREAM_MATCH_CFG(DIR_READ)
		 STREAM_MATCH_SID_VALUE(0xB)
		 STREAM_MATCH_SID_MASK(0x1F)>,
		<15 STREAM_CFG(PTLB_ID(0xC), STLB_ID(0x10), FETCH_SIZE(SIZE1), PTLB_EN, STLB_EN)
		 STREAM_MATCH_CFG(DIR_READ)
		 STREAM_MATCH_SID_VALUE(0x8)
		 STREAM_MATCH_SID_MASK(0x1F)>;
		pmmu1,default_stream =
		<STREAM_CFG(PTLB_ID(0x1), STLB_ID(0x11), FETCH_SIZE(SIZE1), PTLB_EN, STLB_EN)>;
		pmmu1,stream_property =
		<1 STREAM_CFG(PTLB_ID(0x2), STLB_ID(0x12), FETCH_SIZE(SIZE1), PTLB_EN, STLB_EN)
		 STREAM_MATCH_CFG(DIR_WRITE)
		 STREAM_MATCH_SID_VALUE(0x4)
		 STREAM_MATCH_SID_MASK(0xF)>,
		<2 STREAM_CFG(PTLB_ID(0x0), STLB_ID(0x0), FETCH_SIZE(SIZE32), PTLB_EN, STLB_EN)
		 STREAM_MATCH_CFG(DIR_READ)
		 STREAM_MATCH_SID_VALUE(0x1)
		 STREAM_MATCH_SID_MASK(0x3)>,
		<3 STREAM_CFG(PTLB_ID(0x3), STLB_ID(0x13), FETCH_SIZE(SIZE1), PTLB_EN, STLB_EN)
		 STREAM_MATCH_CFG(DIR_WRITE)
		 STREAM_MATCH_SID_VALUE(0x2)
		 STREAM_MATCH_SID_MASK(0x3)>,
		<4 STREAM_CFG(PTLB_ID(0x4), STLB_ID(0x14), FETCH_SIZE(SIZE1), PTLB_EN, STLB_EN)
		 STREAM_MATCH_CFG(DIR_WRITE)
		 STREAM_MATCH_SID_VALUE(0x3)
		 STREAM_MATCH_SID_MASK(0x3)>;
		pmmu2,default_stream =
		<STREAM_CFG(PTLB_ID(0x1), STLB_ID(0x15), FETCH_SIZE(SIZE1), PTLB_EN, STLB_EN)>;
		pmmu2,stream_property =
		<1 STREAM_CFG(PTLB_ID(0x2), STLB_ID(0x16), FETCH_SIZE(SIZE1), PTLB_EN, STLB_EN)
		 STREAM_MATCH_CFG(DIR_WRITE)
		 STREAM_MATCH_SID_VALUE(0x1)
		 STREAM_MATCH_SID_MASK(0x3)>,
		<2 STREAM_CFG(PTLB_ID(0x0), STLB_ID(0x2), FETCH_SIZE(SIZE16), PTLB_EN, STLB_EN)
		 STREAM_MATCH_CFG(DIR_READ)
		 STREAM_MATCH_SID_VALUE(0x2)
		 STREAM_MATCH_SID_MASK(0x3)>;
		pmmu3,default_stream =
		<STREAM_CFG(PTLB_ID(0x2), STLB_ID(0x18), FETCH_SIZE(SIZE1), PTLB_DIS, STLB_DIS)>;
		pmmu3,stream_property =
		<1 STREAM_CFG(PTLB_ID(0x1), STLB_ID(0x3), FETCH_SIZE(SIZE1), PTLB_EN, STLB_EN)
		 STREAM_MATCH_CFG(DIR_READ)
		 STREAM_MATCH_SID_VALUE(0x1)
		 STREAM_MATCH_SID_MASK(0x3)>,
		<2 STREAM_CFG(PTLB_ID(0x0), STLB_ID(0x1), FETCH_SIZE(SIZE32), PTLB_EN, STLB_EN)
		 STREAM_MATCH_CFG(DIR_READ)
		 STREAM_MATCH_SID_VALUE(0x2)
		 STREAM_MATCH_SID_MASK(0x1)>;
	};

	sysmmu_yuvp_s0_stream: sysmmu_yuvp_s0_stream {
		pmmu0,default_stream =
		<STREAM_CFG(PTLB_ID(0x14), STLB_ID(0x15), FETCH_SIZE(SIZE1), PTLB_DIS, STLB_DIS)>;
		pmmu0,stream_property =
		<1 STREAM_CFG(PTLB_ID(0x18), STLB_ID(0x17), FETCH_SIZE(SIZE1), PTLB_DIS, STLB_DIS)
		 STREAM_MATCH_CFG(DIR_WRITE)
		 STREAM_MATCH_SID_VALUE(0x0)
		 STREAM_MATCH_SID_MASK(0x7F)>,
		<2 STREAM_CFG(PTLB_ID(0x0), STLB_ID(0x0), FETCH_SIZE(SIZE1), PTLB_EN, STLB_EN)
		 STREAM_MATCH_CFG(DIR_READ)
		 STREAM_MATCH_SID_VALUE(0x1)
		 STREAM_MATCH_SID_MASK(0x7F)>,
		<3 STREAM_CFG(PTLB_ID(0x1), STLB_ID(0x1), FETCH_SIZE(SIZE1), PTLB_EN, STLB_EN)
		 STREAM_MATCH_CFG(DIR_READ)
		 STREAM_MATCH_SID_VALUE(0x2)
		 STREAM_MATCH_SID_MASK(0x7F)>,
		<4 STREAM_CFG(PTLB_ID(0x2), STLB_ID(0x2), FETCH_SIZE(SIZE1), PTLB_EN, STLB_EN)
		 STREAM_MATCH_CFG(DIR_READ)
		 STREAM_MATCH_SID_VALUE(0x3)
		 STREAM_MATCH_SID_MASK(0x7F)>,
		<5 STREAM_CFG(PTLB_ID(0x3), STLB_ID(0x3), FETCH_SIZE(SIZE1), PTLB_EN, STLB_EN)
		 STREAM_MATCH_CFG(DIR_READ)
		 STREAM_MATCH_SID_VALUE(0x4)
		 STREAM_MATCH_SID_MASK(0x7F)>,
		<6 STREAM_CFG(PTLB_ID(0x4), STLB_ID(0x4), FETCH_SIZE(SIZE1), PTLB_EN, STLB_EN)
		 STREAM_MATCH_CFG(DIR_READ)
		 STREAM_MATCH_SID_VALUE(0x5)
		 STREAM_MATCH_SID_MASK(0x7F)>,
		<7 STREAM_CFG(PTLB_ID(0x15), STLB_ID(0x19), FETCH_SIZE(SIZE16), PTLB_DIS, STLB_DIS)
		 STREAM_MATCH_CFG(DIR_WRITE)
		 STREAM_MATCH_SID_VALUE(0x6)
		 STREAM_MATCH_SID_MASK(0x7F)>,
		<8 STREAM_CFG(PTLB_ID(0x16), STLB_ID(0x1A), FETCH_SIZE(SIZE16), PTLB_DIS, STLB_DIS)
		 STREAM_MATCH_CFG(DIR_READ)
		 STREAM_MATCH_SID_VALUE(0x6)
		 STREAM_MATCH_SID_MASK(0x7F)>,
		<9 STREAM_CFG(PTLB_ID(0x5), STLB_ID(0x5), FETCH_SIZE(SIZE1), PTLB_EN, STLB_EN)
		 STREAM_MATCH_CFG(DIR_READ)
		 STREAM_MATCH_SID_VALUE(0x7)
		 STREAM_MATCH_SID_MASK(0x7F)>,
		<10 STREAM_CFG(PTLB_ID(0x6), STLB_ID(0x6), FETCH_SIZE(SIZE1), PTLB_EN, STLB_EN)
		 STREAM_MATCH_CFG(DIR_READ)
		 STREAM_MATCH_SID_VALUE(0x17)
		 STREAM_MATCH_SID_MASK(0x7F)>,
		<11 STREAM_CFG(PTLB_ID(0x7), STLB_ID(0x7), FETCH_SIZE(SIZE1), PTLB_EN, STLB_EN)
		 STREAM_MATCH_CFG(DIR_WRITE)
		 STREAM_MATCH_SID_VALUE(0x7)
		 STREAM_MATCH_SID_MASK(0x7F)>,
		<12 STREAM_CFG(PTLB_ID(0x8), STLB_ID(0x8), FETCH_SIZE(SIZE1), PTLB_EN, STLB_EN)
		 STREAM_MATCH_CFG(DIR_WRITE)
		 STREAM_MATCH_SID_VALUE(0x7)
		 STREAM_MATCH_SID_MASK(0x7F)>,
		<13 STREAM_CFG(PTLB_ID(0x9), STLB_ID(0x9), FETCH_SIZE(SIZE1), PTLB_EN, STLB_EN)
		 STREAM_MATCH_CFG(DIR_WRITE)
		 STREAM_MATCH_SID_VALUE(0x27)
		 STREAM_MATCH_SID_MASK(0x7F)>,
		<14 STREAM_CFG(PTLB_ID(0xA), STLB_ID(0xA), FETCH_SIZE(SIZE1), PTLB_EN, STLB_EN)
		 STREAM_MATCH_CFG(DIR_WRITE)
		 STREAM_MATCH_SID_VALUE(0x27)
		 STREAM_MATCH_SID_MASK(0x7F)>,
		<15 STREAM_CFG(PTLB_ID(0xB), STLB_ID(0xB), FETCH_SIZE(SIZE1), PTLB_EN, STLB_EN)
		 STREAM_MATCH_CFG(DIR_WRITE)
		 STREAM_MATCH_SID_VALUE(0x47)
		 STREAM_MATCH_SID_MASK(0x7F)>,
		<16 STREAM_CFG(PTLB_ID(0x17), STLB_ID(0x16), FETCH_SIZE(SIZE1), PTLB_DIS, STLB_DIS)
		 STREAM_MATCH_CFG(DIR_READ)
		 STREAM_MATCH_SID_VALUE(0x8)
		 STREAM_MATCH_SID_MASK(0x7F)>,
		<17 STREAM_CFG(PTLB_ID(0xC), STLB_ID(0xC), FETCH_SIZE(SIZE1), PTLB_EN, STLB_EN)
		 STREAM_MATCH_CFG(DIR_WRITE)
		 STREAM_MATCH_SID_VALUE(0x8)
		 STREAM_MATCH_SID_MASK(0x7F)>,
		<18 STREAM_CFG(PTLB_ID(0xD), STLB_ID(0xD), FETCH_SIZE(SIZE1), PTLB_EN, STLB_EN)
		 STREAM_MATCH_CFG(DIR_WRITE)
		 STREAM_MATCH_SID_VALUE(0x7)
		 STREAM_MATCH_SID_MASK(0x7F)>,
		<19 STREAM_CFG(PTLB_ID(0xE), STLB_ID(0xE), FETCH_SIZE(SIZE1), PTLB_EN, STLB_EN)
		 STREAM_MATCH_CFG(DIR_WRITE)
		 STREAM_MATCH_SID_VALUE(0x28)
		 STREAM_MATCH_SID_MASK(0x7F)>,
		<20 STREAM_CFG(PTLB_ID(0xF), STLB_ID(0xF), FETCH_SIZE(SIZE1), PTLB_EN, STLB_EN)
		 STREAM_MATCH_CFG(DIR_WRITE)
		 STREAM_MATCH_SID_VALUE(0x27)
		 STREAM_MATCH_SID_MASK(0x7F)>,
		<21 STREAM_CFG(PTLB_ID(0x10), STLB_ID(0x10), FETCH_SIZE(SIZE1), PTLB_EN, STLB_EN)
		 STREAM_MATCH_CFG(DIR_WRITE)
		 STREAM_MATCH_SID_VALUE(0x48)
		 STREAM_MATCH_SID_MASK(0x7F)>,
		<22 STREAM_CFG(PTLB_ID(0x11), STLB_ID(0x11), FETCH_SIZE(SIZE1), PTLB_EN, STLB_EN)
		 STREAM_MATCH_CFG(DIR_WRITE)
		 STREAM_MATCH_SID_VALUE(0x9)
		 STREAM_MATCH_SID_MASK(0x7F)>,
		<23 STREAM_CFG(PTLB_ID(0x12), STLB_ID(0x12), FETCH_SIZE(SIZE1), PTLB_EN, STLB_EN)
		 STREAM_MATCH_CFG(DIR_WRITE)
		 STREAM_MATCH_SID_VALUE(0x29)
		 STREAM_MATCH_SID_MASK(0x7F)>,
		<24 STREAM_CFG(PTLB_ID(0x13), STLB_ID(0x13), FETCH_SIZE(SIZE1), PTLB_EN, STLB_EN)
		 STREAM_MATCH_CFG(DIR_WRITE)
		 STREAM_MATCH_SID_VALUE(0x49)
		 STREAM_MATCH_SID_MASK(0x7F)>,
		<25 STREAM_CFG(PTLB_ID(0x19), STLB_ID(0x14), FETCH_SIZE(SIZE1), PTLB_DIS, STLB_DIS)
		 STREAM_MATCH_CFG(DIR_WRITE)
		 STREAM_MATCH_SID_VALUE(0xA)
		 STREAM_MATCH_SID_MASK(0x7F)>,
		<26 STREAM_CFG(PTLB_ID(0x1A), STLB_ID(0x18), FETCH_SIZE(SIZE1), PTLB_DIS, STLB_DIS)
		 STREAM_MATCH_CFG(DIR_READ)
		 STREAM_MATCH_SID_VALUE(0xB)
		 STREAM_MATCH_SID_MASK(0x7F)>;
	};

	sysmmu_m2m_s0_stream: sysmmu_m2m_s0_stream {
		pmmu0,default_stream =
		<STREAM_CFG(PTLB_ID(0x1), STLB_ID(0x11), FETCH_SIZE(SIZE32), PTLB_DIS, STLB_EN)>;
		pmmu0,stream_property =
		<1 STREAM_CFG(PTLB_ID(0x4), STLB_ID(0x15), FETCH_SIZE(SIZE1), PTLB_EN, STLB_DIS)
		 STREAM_MATCH_CFG(DIR_READ)
		 STREAM_MATCH_SID_VALUE(0xA)
		 STREAM_MATCH_SID_MASK(0x3F)>,
		<2 STREAM_CFG(PTLB_ID(0x5), STLB_ID(0x6), FETCH_SIZE(SIZE1), PTLB_EN, STLB_EN)
		 STREAM_MATCH_CFG(DIR_WRITE)
		 STREAM_MATCH_SID_VALUE(0x22)
		 STREAM_MATCH_SID_MASK(0x3F)>,
		<3 STREAM_CFG(PTLB_ID(0x6), STLB_ID(0x7), FETCH_SIZE(SIZE1), PTLB_EN, STLB_EN)
		 STREAM_MATCH_CFG(DIR_WRITE)
		 STREAM_MATCH_SID_VALUE(0x32)
		 STREAM_MATCH_SID_MASK(0x3F)>,
		<4 STREAM_CFG(PTLB_ID(0x3), STLB_ID(0x12), FETCH_SIZE(SIZE8), PTLB_DIS, STLB_DIS)
		 STREAM_MATCH_CFG(DIR_RW)
		 STREAM_MATCH_SID_VALUE(0x0)
		 STREAM_MATCH_SID_MASK(0x3F)>,
		<5 STREAM_CFG(PTLB_ID(0x9), STLB_ID(0x18), FETCH_SIZE(SIZE1), PTLB_DIS, STLB_DIS)
		 STREAM_MATCH_CFG(DIR_WRITE)
		 STREAM_MATCH_SID_VALUE(0xA)
		 STREAM_MATCH_SID_MASK(0x3F)>,
		<6 STREAM_CFG(PTLB_ID(0x0), STLB_ID(0x0), FETCH_SIZE(SIZE8), PTLB_EN, STLB_EN)
		 STREAM_MATCH_CFG(DIR_READ)
		 STREAM_MATCH_SID_VALUE(0x3)
		 STREAM_MATCH_SID_MASK(0xF)>,
		<7 STREAM_CFG(PTLB_ID(0x7), STLB_ID(0x8), FETCH_SIZE(SIZE1), PTLB_EN, STLB_EN)
		 STREAM_MATCH_CFG(DIR_READ)
		 STREAM_MATCH_SID_VALUE(0xB)
		 STREAM_MATCH_SID_MASK(0xF)>,
		<8 STREAM_CFG(PTLB_ID(0x2), STLB_ID(0x3), FETCH_SIZE(SIZE4), PTLB_EN, STLB_EN)
		 STREAM_MATCH_CFG(DIR_WRITE)
		 STREAM_MATCH_SID_VALUE(0x3)
		 STREAM_MATCH_SID_MASK(0xF)>,
		<9 STREAM_CFG(PTLB_ID(0x8), STLB_ID(0x9), FETCH_SIZE(SIZE1), PTLB_EN, STLB_EN)
		 STREAM_MATCH_CFG(DIR_WRITE)
		 STREAM_MATCH_SID_VALUE(0xB)
		 STREAM_MATCH_SID_MASK(0xF)>,
		<10 STREAM_CFG(PTLB_ID(0xA), STLB_ID(0x16), FETCH_SIZE(SIZE1), PTLB_DIS, STLB_DIS)
		 STREAM_MATCH_CFG(DIR_READ)
		 STREAM_MATCH_SID_VALUE(0x4)
		 STREAM_MATCH_SID_MASK(0xF)>;
		pmmu1,default_stream =
		<STREAM_CFG(PTLB_ID(0xD), STLB_ID(0x17), FETCH_SIZE(SIZE1), PTLB_DIS, STLB_DIS)>;
		pmmu1,stream_property =
		<1 STREAM_CFG(PTLB_ID(0x4), STLB_ID(0x13), FETCH_SIZE(SIZE1), PTLB_DIS, STLB_DIS)
		 STREAM_MATCH_CFG(DIR_READ)
		 STREAM_MATCH_SID_VALUE(0x1)
		 STREAM_MATCH_SID_MASK(0x1)>,
		<2 STREAM_CFG(PTLB_ID(0x6), STLB_ID(0xA), FETCH_SIZE(SIZE1), PTLB_EN, STLB_EN)
		 STREAM_MATCH_CFG(DIR_WRITE)
		 STREAM_MATCH_SID_VALUE(0x2)
		 STREAM_MATCH_SID_MASK(0x1)>,
		<3 STREAM_CFG(PTLB_ID(0x5), STLB_ID(0x14), FETCH_SIZE(SIZE1), PTLB_DIS, STLB_DIS)
		 STREAM_MATCH_CFG(DIR_READ)
		 STREAM_MATCH_SID_VALUE(0x3)
		 STREAM_MATCH_SID_MASK(0x1)>,
		<4 STREAM_CFG(PTLB_ID(0x7), STLB_ID(0xB), FETCH_SIZE(SIZE1), PTLB_EN, STLB_EN)
		 STREAM_MATCH_CFG(DIR_READ)
		 STREAM_MATCH_SID_VALUE(0x4)
		 STREAM_MATCH_SID_MASK(0x1)>,
		<5 STREAM_CFG(PTLB_ID(0x8), STLB_ID(0xC), FETCH_SIZE(SIZE1), PTLB_EN, STLB_EN)
		 STREAM_MATCH_CFG(DIR_WRITE)
		 STREAM_MATCH_SID_VALUE(0x5)
		 STREAM_MATCH_SID_MASK(0x1)>,
		<6 STREAM_CFG(PTLB_ID(0x0), STLB_ID(0x1), FETCH_SIZE(SIZE8), PTLB_DIS, STLB_EN)
		 STREAM_MATCH_CFG(DIR_READ)
		 STREAM_MATCH_SID_VALUE(0x6)
		 STREAM_MATCH_SID_MASK(0x3F)>,
		<7 STREAM_CFG(PTLB_ID(0x9), STLB_ID(0xD), FETCH_SIZE(SIZE1), PTLB_DIS, STLB_EN)
		 STREAM_MATCH_CFG(DIR_READ)
		 STREAM_MATCH_SID_VALUE(0x16)
		 STREAM_MATCH_SID_MASK(0x3F)>,
		<8 STREAM_CFG(PTLB_ID(0x2), STLB_ID(0x4), FETCH_SIZE(SIZE4), PTLB_DIS, STLB_EN)
		 STREAM_MATCH_CFG(DIR_WRITE)
		 STREAM_MATCH_SID_VALUE(0x6)
		 STREAM_MATCH_SID_MASK(0x3F)>,
		<9 STREAM_CFG(PTLB_ID(0xA), STLB_ID(0xE), FETCH_SIZE(SIZE1), PTLB_DIS, STLB_EN)
		 STREAM_MATCH_CFG(DIR_WRITE)
		 STREAM_MATCH_SID_VALUE(0x16)
		 STREAM_MATCH_SID_MASK(0x3F)>,
		<10 STREAM_CFG(PTLB_ID(0x3), STLB_ID(0x5), FETCH_SIZE(SIZE4), PTLB_DIS, STLB_EN)
		 STREAM_MATCH_CFG(DIR_WRITE)
		 STREAM_MATCH_SID_VALUE(0x26)
		 STREAM_MATCH_SID_MASK(0x3F)>,
		<11 STREAM_CFG(PTLB_ID(0xB), STLB_ID(0xF), FETCH_SIZE(SIZE1), PTLB_DIS, STLB_EN)
		 STREAM_MATCH_CFG(DIR_WRITE)
		 STREAM_MATCH_SID_VALUE(0x36)
		 STREAM_MATCH_SID_MASK(0x3F)>,
		<12 STREAM_CFG(PTLB_ID(0x1), STLB_ID(0x2), FETCH_SIZE(SIZE8), PTLB_DIS, STLB_EN)
		 STREAM_MATCH_CFG(DIR_READ)
		 STREAM_MATCH_SID_VALUE(0x7)
		 STREAM_MATCH_SID_MASK(0x1)>,
		<13 STREAM_CFG(PTLB_ID(0xC), STLB_ID(0x10), FETCH_SIZE(SIZE1), PTLB_DIS, STLB_EN)
		 STREAM_MATCH_CFG(DIR_READ)
		 STREAM_MATCH_SID_VALUE(0x17)
		 STREAM_MATCH_SID_MASK(0x1)>,
		<14 STREAM_CFG(PTLB_ID(0xE), STLB_ID(0x19), FETCH_SIZE(SIZE1), PTLB_DIS, STLB_DIS)
		 STREAM_MATCH_CFG(DIR_READ)
		 STREAM_MATCH_SID_VALUE(0x8)
		 STREAM_MATCH_SID_MASK(0x1)>;
	};

	sysmmu_mfc_s0_stream: sysmmu_mfc_s0_stream {
		pmmu0,default_stream =
		<STREAM_CFG(PTLB_ID(0x1), STLB_ID(0x0), FETCH_SIZE(SIZE4), PTLB_DIS, STLB_DIS)>;
		pmmu0,stream_property =
		<1 STREAM_CFG(PTLB_ID(0x0), STLB_ID(0x1), FETCH_SIZE(SIZE4), PTLB_DIS, STLB_EN)
		 STREAM_MATCH_CFG(DIR_RW)
		 STREAM_MATCH_SID_VALUE(0x1)
		 STREAM_MATCH_SID_MASK(0x3)>,
		<2 STREAM_CFG(PTLB_ID(0x2), STLB_ID(0x2), FETCH_SIZE(SIZE1), PTLB_DIS, STLB_DIS)
		 STREAM_MATCH_CFG(DIR_WRITE)
		 STREAM_MATCH_SID_VALUE(0x2)
		 STREAM_MATCH_SID_MASK(0x3)>;
	};

	sysmmu_mfc_s1_stream: sysmmu_mfc_s1_stream {
		pmmu0,default_stream =
		<STREAM_CFG(PTLB_ID(0x0), STLB_ID(0x0), FETCH_SIZE(SIZE32), PTLB_DIS, STLB_EN)>;
		pmmu0,stream_property =
		<1 STREAM_CFG(PTLB_ID(0x4), STLB_ID(0x4), FETCH_SIZE(SIZE1), PTLB_DIS, STLB_EN)
		 STREAM_MATCH_CFG(DIR_READ)
		 STREAM_MATCH_SID_VALUE(0x2)
		 STREAM_MATCH_SID_MASK(0xF)>,
		<2 STREAM_CFG(PTLB_ID(0x2), STLB_ID(0x2), FETCH_SIZE(SIZE16), PTLB_DIS, STLB_EN)
		 STREAM_MATCH_CFG(DIR_READ)
		 STREAM_MATCH_SID_VALUE(0x4)
		 STREAM_MATCH_SID_MASK(0xF)>,
		<3 STREAM_CFG(PTLB_ID(0x5), STLB_ID(0x5), FETCH_SIZE(SIZE1), PTLB_DIS, STLB_EN)
		 STREAM_MATCH_CFG(DIR_READ)
		 STREAM_MATCH_SID_VALUE(0x6)
		 STREAM_MATCH_SID_MASK(0xF)>,
		<4 STREAM_CFG(PTLB_ID(0x3), STLB_ID(0x3), FETCH_SIZE(SIZE16), PTLB_DIS, STLB_EN)
		 STREAM_MATCH_CFG(DIR_WRITE)
		 STREAM_MATCH_SID_VALUE(0x0)
		 STREAM_MATCH_SID_MASK(0xF)>,
		<5 STREAM_CFG(PTLB_ID(0x6), STLB_ID(0x6), FETCH_SIZE(SIZE1), PTLB_DIS, STLB_EN)
		 STREAM_MATCH_CFG(DIR_WRITE)
		 STREAM_MATCH_SID_VALUE(0x2)
		 STREAM_MATCH_SID_MASK(0xF)>,
		<6 STREAM_CFG(PTLB_ID(0x1), STLB_ID(0x1), FETCH_SIZE(SIZE32), PTLB_DIS, STLB_EN)
		 STREAM_MATCH_CFG(DIR_WRITE)
		 STREAM_MATCH_SID_VALUE(0x1)
		 STREAM_MATCH_SID_MASK(0xF)>,
		<7 STREAM_CFG(PTLB_ID(0x7), STLB_ID(0x7), FETCH_SIZE(SIZE1), PTLB_DIS, STLB_EN)
		 STREAM_MATCH_CFG(DIR_WRITE)
		 STREAM_MATCH_SID_VALUE(0x3)
		 STREAM_MATCH_SID_MASK(0xF)>;
	};
};
